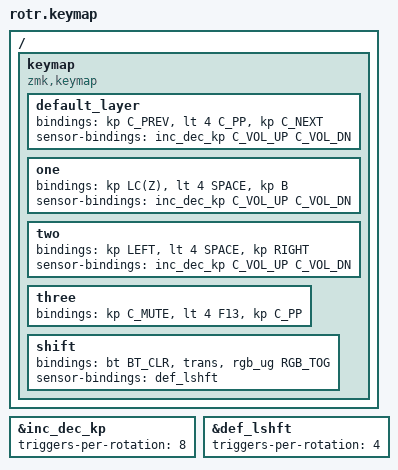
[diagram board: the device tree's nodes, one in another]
#include <behaviors.dtsi>
#include <dt-bindings/zmk/keys.h>
#include <dt-bindings/zmk/rgb.h>
#include <dt-bindings/zmk/bt.h>

&inc_dec_kp {
	triggers-per-rotation = <8>;
};
&def_lshft {
	triggers-per-rotation = <4>;
};

/ {
	keymap {
		compatible = "zmk,keymap";

		default_layer {
			//RED		PREV | PAUSE/PLAY | NEXT	VOLUME CONTROL
			bindings = <&kp C_PREV &lt 4 C_PP &kp C_NEXT>;
			sensor-bindings = <&inc_dec_kp C_VOL_UP C_VOL_DN>;
		};
		one {
			//GREEN		CTRL Z | SPACE | B	SIDE SCROLL CONTROL
			bindings = <&kp LC(Z) &lt 4 SPACE &kp B>;
			sensor-bindings = <&inc_dec_kp C_VOL_UP C_VOL_DN>;
		};
		two {
			//BLUE		LEFT | LAYER | RIGHT	SCROLLDOWN AND SCROLLEUP
			bindings = <&kp LEFT &lt 4 SPACE &kp RIGHT>;
			sensor-bindings = <&inc_dec_kp C_VOL_UP C_VOL_DN>;
		};
		three {
			//Other GREEN	MUTE | LAYER | PAUSE/PLAY	
			bindings = <&kp C_MUTE &lt 4 F13 &kp C_PP>;
		};
		shift {
			//PREV | PLAY/PAUSE | NEXT
			bindings = <&bt BT_CLR &trans &rgb_ug RGB_TOG>;
			sensor-bindings = <&def_lshft>;
		};
	};
};
